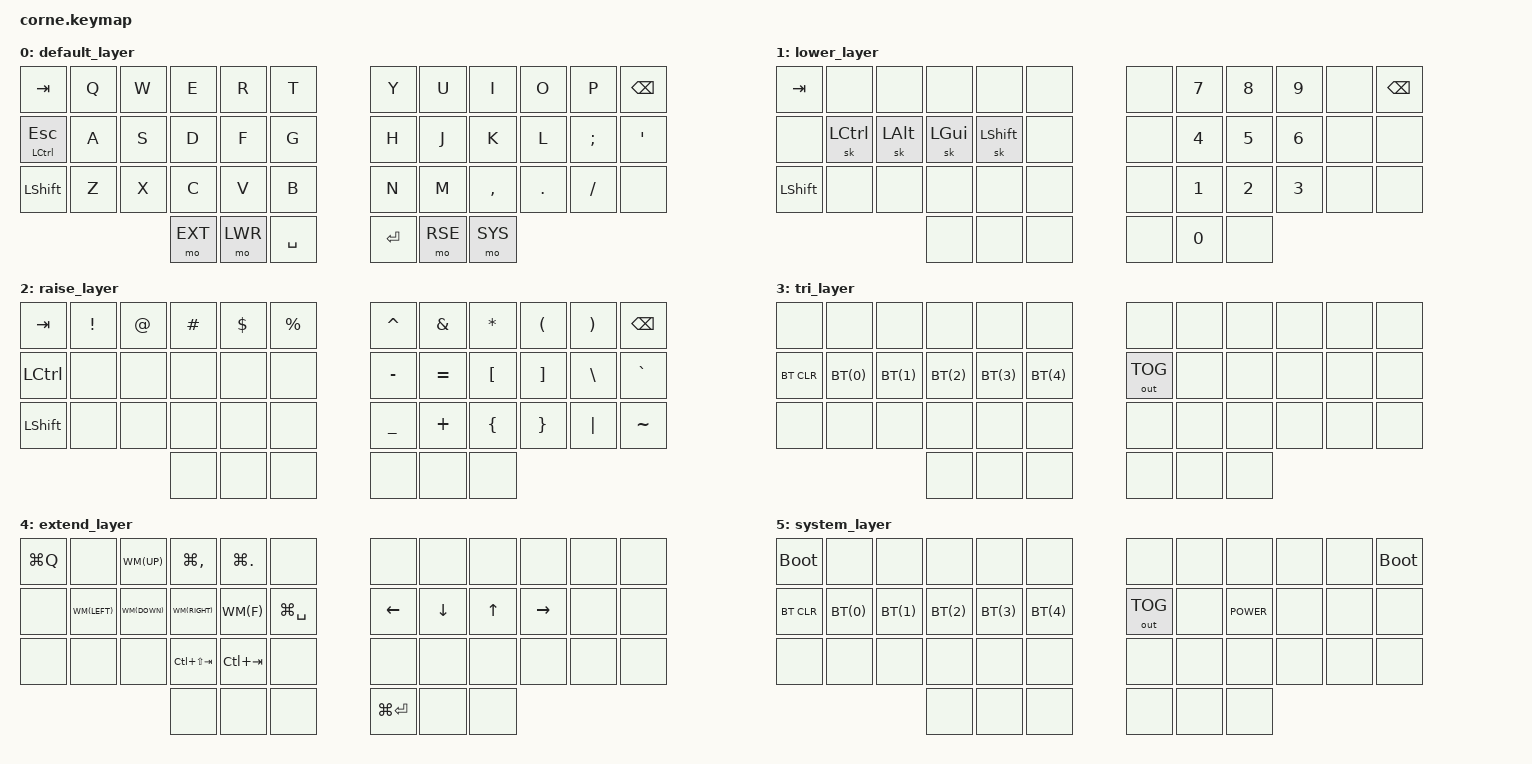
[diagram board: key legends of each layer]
/*
 * Copyright (c) 2020 The ZMK Contributors
 *
 * SPDX-License-Identifier: MIT
 */

#include <behaviors.dtsi>
#include <dt-bindings/zmk/keys.h>
#include <dt-bindings/zmk/bt.h>
#include <dt-bindings/zmk/outputs.h>

#define LWR 1
#define RSE 2
#define TRI 3
#define EXT 4
#define SYS 5

#define COMBO(NAME, BINDINGS, KEYPOS) \
  combo_##NAME { \
    timeout-ms = <50>; \
    bindings = <BINDINGS>; \
    key-positions = <KEYPOS>; \
    layers = <0>; \
  };

#define BT(x) &bt BT_SEL x
#define WM(x) &ht LG(LS(x)) LG(x)

/ {
    behaviors {
        ht: hold_tap {
            compatible = "zmk,behavior-hold-tap";
            #binding-cells = <2>;
            flavor = "balanced";
            tapping-term-ms = <200>;
            quick-tap-ms = <0>;
            bindings = <&kp>, <&kp>;
        };
    };

    conditional_layers {
        compatible = "zmk,conditional-layers";
        tri_layer {
            if-layers = <LWR RSE>;
            then-layer = <TRI>;
        };
    };

    combos {
        compatible = "zmk,combos";

        COMBO(undo, &kp LC(Z), 25 26)
        COMBO(cut, &kp LC(X), 26 27)
        COMBO(copy, &kp LC(C), 27 28)
        COMBO(paste, &kp LC(V), 28 29)
    };

    keymap {
        compatible = "zmk,keymap";

        default_layer {
            bindings = <
                // ╭──────────┬──────────┬──────────┬──────────┬──────────┬──────────╮   ╭──────────┬──────────┬──────────┬──────────┬──────────┬──────────╮
                // │  TAB     │  Q       │  W       │  E       │  R       │  T       │   │  Y       │  U       │  I       │  O       │  P       │  BSPC    │
                     &kp TAB    &kp Q      &kp W      &kp E      &kp R      &kp T          &kp Y      &kp U      &kp I      &kp O      &kp P      &kp BSPC
                // ├──────────┼──────────┼──────────┼──────────┼──────────┼──────────┤   ├──────────┼──────────┼──────────┼──────────┼──────────┼──────────┤
                // │ CTRL/ESC │  A       │  S       │  D       │  F       │  G       │   │  H       │  J       │  K       │  L       │  ; :     │  ' "     │
                  &mt LCTRL ESC &kp A      &kp S      &kp D      &kp F      &kp G          &kp H      &kp J      &kp K      &kp L      &kp SEMI   &kp SQT
                // ├──────────┼──────────┼──────────┼──────────┼──────────┼──────────┤   ├──────────┼──────────┼──────────┼──────────┼──────────┼──────────┤
                // │  SHIFT   │  Z       │  X       │  C       │  V       │  B       │   │  N       │  M       │  , <     │  . >     │  / ?     │          │
                     &kp LSHFT  &kp Z      &kp X      &kp C      &kp V      &kp B          &kp N      &kp M      &kp COMMA  &kp DOT    &kp FSLH   &none
                // ╰──────────┴──────────┴──────────┼──────────┼──────────┼──────────┤   ├──────────┼──────────┼──────────┼──────────┴──────────┴──────────╯
                //                                  │  EXTEND  │  LOWER   │  SPACE   │   │  ENTER   │  RAISE   │  SYSTEM  │
                                                      &mo EXT    &mo LWR    &kp SPACE      &kp RET    &mo RSE    &mo SYS
                //                                  ╰──────────┴──────────┴──────────╯   ╰──────────┴──────────┴──────────╯
            >;
        };

        lower_layer {
            bindings = <
                // ╭──────────┬──────────┬──────────┬──────────┬──────────┬──────────╮   ╭──────────┬──────────┬──────────┬──────────┬──────────┬──────────╮
                // │  TAB     │          │          │          │          │          │   │          │  7       │  8       │  9       │          │  BSPC    │
                     &kp TAB    &none      &none      &none      &none      &none          &none      &kp N7     &kp N8     &kp N9     &none      &kp BSPC
                // ├──────────┼──────────┼──────────┼──────────┼──────────┼──────────┤   ├──────────┼──────────┼──────────┼──────────┼──────────┼──────────┤
                // │          │  CTRL    │  ALT     │  GUI     │  SHIFT   │          │   │          │  4       │  5       │  6       │          │          │
                     &none      &sk LCTRL  &sk LALT   &sk LGUI   &sk LSHFT  &none          &none      &kp N4     &kp N5     &kp N6     &none      &none
                // ├──────────┼──────────┼──────────┼──────────┼──────────┼──────────┤   ├──────────┼──────────┼──────────┼──────────┼──────────┼──────────┤
                // │  SHIFT   │          │          │          │          │          │   │          │  1       │  2       │  3       │          │          │
                     &kp LSHFT  &none      &none      &none      &none      &none          &none      &kp N1     &kp N2     &kp N3     &none      &none
                // ╰──────────┴──────────┴──────────┼──────────┼──────────┼──────────┤   ├──────────┼──────────┼──────────┼──────────┴──────────┴──────────╯
                //                                  │          │          │          │   │          │  0       │          │
                                                      &none      &none      &none          &none      &kp N0     &none
                //                                  ╰──────────┴──────────┴──────────╯   ╰──────────┴──────────┴──────────╯
            >;
        };

        raise_layer {
            bindings = <
                // ╭──────────┬──────────┬──────────┬──────────┬──────────┬──────────╮   ╭──────────┬──────────┬──────────┬──────────┬──────────┬──────────╮
                // │  TAB     │  !       │  @       │  #       │  $       │  %       │   │  ^       │  &       │  *       │  (       │  )       │  BSPC    │
                     &kp TAB    &kp EXCL   &kp AT     &kp HASH   &kp DLLR   &kp PRCNT      &kp CARET  &kp AMPS   &kp ASTRK  &kp LPAR   &kp RPAR   &kp BSPC
                // ├──────────┼──────────┼──────────┼──────────┼──────────┼──────────┤   ├──────────┼──────────┼──────────┼──────────┼──────────┼──────────┤
                // │  CTRL    │          │          │          │          │          │   │  -       │  =       │  [       │  ]       │  \       │  `       │
                     &kp LCTRL  &none      &none      &none      &none      &none          &kp MINUS  &kp EQUAL  &kp LBKT   &kp RBKT   &kp BSLH   &kp GRAVE
                // ├──────────┼──────────┼──────────┼──────────┼──────────┼──────────┤   ├──────────┼──────────┼──────────┼──────────┼──────────┼──────────┤
                // │  SHIFT   │          │          │          │          │          │   │  _       │  +       │  {       │  }       │  |       │  ~       │
                     &kp LSHFT  &none      &none      &none      &none      &none          &kp UNDER  &kp PLUS   &kp LBRC   &kp RBRC   &kp PIPE   &kp TILDE
                // ╰──────────┴──────────┴──────────┼──────────┼──────────┼──────────┤   ├──────────┼──────────┼──────────┼──────────┴──────────┴──────────╯
                //                                  │          │          │          │   │          │          │          │
                                                      &none      &none      &none          &none      &none      &none
                //                                  ╰──────────┴──────────┴──────────╯   ╰──────────┴──────────┴──────────╯
            >;
        };

        tri_layer {
            bindings = <
                // ╭──────────┬──────────┬──────────┬──────────┬──────────┬──────────╮   ╭──────────┬──────────┬──────────┬──────────┬──────────┬──────────╮
                // │          │          │          │          │          │          │   │          │          │          │          │          │          │
                     &none      &none      &none      &none      &none      &none          &none      &none      &none      &none      &none      &none
                // ├──────────┼──────────┼──────────┼──────────┼──────────┼──────────┤   ├──────────┼──────────┼──────────┼──────────┼──────────┼──────────┤
                // │  BTCLR   │  BT1     │  BT2     │  BT3     │  BT4     │  BT5     │   │          │          │          │          │          │          │
                    &bt BT_CLR  BT(0)      BT(1)      BT(2)      BT(3)      BT(4)        &out OUT_TOG &none      &none      &none      &none      &none
                // ├──────────┼──────────┼──────────┼──────────┼──────────┼──────────┤   ├──────────┼──────────┼──────────┼──────────┼──────────┼──────────┤
                // │          │          │          │          │          │          │   │          │          │          │          │          │          │
                     &none      &none      &none      &none      &none      &none          &none      &none      &none      &none      &none      &none
                // ╰──────────┴──────────┴──────────┼──────────┼──────────┼──────────┤   ├──────────┼──────────┼──────────┼──────────┴──────────┴──────────╯
                //                                  │          │          │          │   │          │          │          │
                                                      &none      &none      &none          &none      &none      &none
                //                                  ╰──────────┴──────────┴──────────╯   ╰──────────┴──────────┴──────────╯
            >;
        };

        extend_layer {
            bindings = <
                // ╭──────────┬──────────┬──────────┬──────────┬──────────┬──────────╮   ╭──────────┬──────────┬──────────┬──────────┬──────────┬──────────╮
                // │  QUIT    │          │ ABOVE SP │ PREV SP  │ NEXT SP  │          │   │          │          │          │          │          │          │
                     &kp LG(Q)  &none      WM(UP)    &kp LG(COMMA) &kp LG(DOT) &none       &none      &none      &none      &none      &none      &none
                // ├──────────┼──────────┼──────────┼──────────┼──────────┼──────────┤   ├──────────┼──────────┼──────────┼──────────┼──────────┼──────────┤
                // │          │ LEFT SP  │ BELOW SP │ RIGHT SP │ MAXIMISE │ LAUNCH   │   │  LEFT    │  DOWN    │  UP      │  RIGHT   │          │          │
                     &none      WM(LEFT)   WM(DOWN)   WM(RIGHT)  WM(F)     &kp LG(SPACE)   &kp LEFT   &kp DOWN   &kp UP     &kp RIGHT  &none      &none
                // ├──────────┼──────────┼──────────┼──────────┼──────────┼──────────┤   ├──────────┼──────────┼──────────┼──────────┼──────────┼──────────┤
                // │          │          │          │ PREV TAB │ NEXT TAB │          │   │          │          │          │          │          │          │
                     &none      &none      &none     &kp LC(LS(TAB)) &kp LC(TAB) &none     &none      &none      &none      &none      &none      &none
                // ╰──────────┴──────────┴──────────┼──────────┼──────────┼──────────┤   ├──────────┼──────────┼──────────┼──────────┴──────────┴──────────╯
                //                                  │          │          │          │   │ TERMINAL │          │          │
                                                      &none      &none      &none         &kp LG(RET) &none      &none
                //                                  ╰──────────┴──────────┴──────────╯   ╰──────────┴──────────┴──────────╯
            >;
        };

        system_layer {
            bindings = <
                // ╭──────────┬──────────┬──────────┬──────────┬──────────┬──────────╮   ╭──────────┬──────────┬──────────┬──────────┬──────────┬──────────╮
                // │          │          │          │          │          │          │   │          │          │          │          │          │          │
                    &bootloader &none      &none      &none      &none      &none          &none      &none      &none      &none      &none     &bootloader
                // ├──────────┼──────────┼──────────┼──────────┼──────────┼──────────┤   ├──────────┼──────────┼──────────┼──────────┼──────────┼──────────┤
                // │  BTCLR   │  BT1     │  BT2     │  BT3     │  BT4     │  BT5     │   │          │          │          │          │          │          │
                    &bt BT_CLR  BT(0)      BT(1)      BT(2)      BT(3)      BT(4)        &out OUT_TOG &none     &kp C_POWER &none      &none      &none
                // ├──────────┼──────────┼──────────┼──────────┼──────────┼──────────┤   ├──────────┼──────────┼──────────┼──────────┼──────────┼──────────┤
                // │          │          │          │          │          │          │   │          │          │          │          │          │          │
                     &none      &none      &none      &none      &none      &none          &none      &none      &none      &none      &none      &none
                // ╰──────────┴──────────┴──────────┼──────────┼──────────┼──────────┤   ├──────────┼──────────┼──────────┼──────────┴──────────┴──────────╯
                //                                  │          │          │          │   │          │          │          │
                                                      &none      &none      &none          &none      &none      &none
                //                                  ╰──────────┴──────────┴──────────╯   ╰──────────┴──────────┴──────────╯
            >;
        };
    };
};

